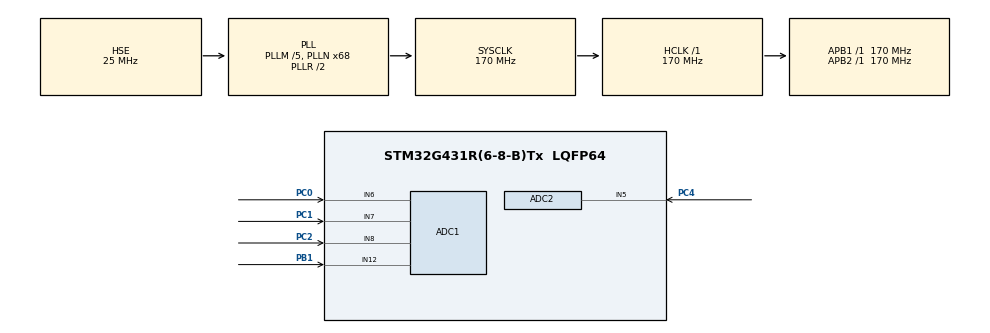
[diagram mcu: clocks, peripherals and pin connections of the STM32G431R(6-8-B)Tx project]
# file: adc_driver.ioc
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ADC1.Channel-1\#ChannelRegularConversion=ADC_CHANNEL_6
ADC1.Channel-2\#ChannelRegularConversion=ADC_CHANNEL_7
ADC1.Channel-3\#ChannelRegularConversion=ADC_CHANNEL_8
ADC1.Channel-4\#ChannelRegularConversion=ADC_CHANNEL_12
ADC1.ContinuousConvMode=ENABLE
ADC1.DMAContinuousRequests=ENABLE
ADC1.NbrOfConversion=4
ADC1.NbrOfConversionFlag=1
ADC1.OffsetNumber-1\#ChannelRegularConversion=ADC_OFFSET_NONE
ADC1.OffsetNumber-2\#ChannelRegularConversion=ADC_OFFSET_NONE
ADC1.OffsetNumber-3\#ChannelRegularConversion=ADC_OFFSET_NONE
ADC1.OffsetNumber-4\#ChannelRegularConversion=ADC_OFFSET_NONE
ADC1.Rank-1\#ChannelRegularConversion=1
ADC1.Rank-2\#ChannelRegularConversion=2
ADC1.Rank-3\#ChannelRegularConversion=3
ADC1.Rank-4\#ChannelRegularConversion=4
ADC1.SamplingTime-1\#ChannelRegularConversion=ADC_SAMPLETIME_47CYCLES_5
ADC1.SamplingTime-2\#ChannelRegularConversion=ADC_SAMPLETIME_47CYCLES_5
ADC1.SamplingTime-3\#ChannelRegularConversion=ADC_SAMPLETIME_47CYCLES_5
ADC1.SamplingTime-4\#ChannelRegularConversion=ADC_SAMPLETIME_47CYCLES_5
ADC1.master=1
ADC2.Channel-1\#ChannelRegularConversion=ADC_CHANNEL_5
ADC2.ContinuousConvMode=ENABLE
ADC2.DMAContinuousRequests=ENABLE
ADC2.NbrOfConversionFlag=1
ADC2.OffsetNumber-1\#ChannelRegularConversion=ADC_OFFSET_NONE
ADC2.Rank-1\#ChannelRegularConversion=1
ADC2.SamplingTime-1\#ChannelRegularConversion=ADC_SAMPLETIME_47CYCLES_5
Dma.ADC1.1.Direction=DMA_PERIPH_TO_MEMORY
Dma.ADC1.1.EventEnable=DISABLE
Dma.ADC1.1.Instance=DMA1_Channel2
Dma.ADC1.1.MemDataAlignment=DMA_MDATAALIGN_HALFWORD
Dma.ADC1.1.MemInc=DMA_MINC_ENABLE
Dma.ADC1.1.Mode=DMA_CIRCULAR
Dma.ADC1.1.PeriphDataAlignment=DMA_PDATAALIGN_HALFWORD
Dma.ADC1.1.PeriphInc=DMA_PINC_DISABLE
Dma.ADC1.1.Polarity=HAL_DMAMUX_REQ_GEN_RISING
Dma.ADC1.1.Priority=DMA_PRIORITY_LOW
Dma.ADC1.1.RequestNumber=1
Dma.ADC1.1.SignalID=NONE
Dma.ADC1.1.SyncEnable=DISABLE
Dma.ADC1.1.SyncPolarity=HAL_DMAMUX_SYNC_NO_EVENT
Dma.ADC1.1.SyncRequestNumber=1
Dma.ADC1.1.SyncSignalID=NONE
Dma.ADC2.0.Direction=DMA_PERIPH_TO_MEMORY
Dma.ADC2.0.EventEnable=DISABLE
Dma.ADC2.0.Instance=DMA1_Channel1
Dma.ADC2.0.MemDataAlignment=DMA_MDATAALIGN_HALFWORD
Dma.ADC2.0.MemInc=DMA_MINC_ENABLE
Dma.ADC2.0.Mode=DMA_CIRCULAR
Dma.ADC2.0.PeriphDataAlignment=DMA_PDATAALIGN_HALFWORD
Dma.ADC2.0.PeriphInc=DMA_PINC_DISABLE
Dma.ADC2.0.Polarity=HAL_DMAMUX_REQ_GEN_RISING
Dma.ADC2.0.Priority=DMA_PRIORITY_LOW
Dma.ADC2.0.RequestNumber=1
Dma.ADC2.0.SignalID=NONE
Dma.ADC2.0.SyncEnable=DISABLE
Dma.ADC2.0.SyncPolarity=HAL_DMAMUX_SYNC_NO_EVENT
Dma.ADC2.0.SyncRequestNumber=1
Dma.ADC2.0.SyncSignalID=NONE
Dma.Request0=ADC2
Dma.Request1=ADC1
Mcu.Family=STM32G4
Mcu.Name=STM32G431R(6-8-B)Tx
Mcu.Package=LQFP64
NVIC.DMA1_Channel1_IRQn=true\:0\:0\:false\:false\:true\:false\:true\:true
NVIC.DMA1_Channel2_IRQn=true\:0\:0\:false\:false\:true\:false\:true\:true
NVIC.PriorityGroup=NVIC_PRIORITYGROUP_4
PA13.Mode=Serial_Wire
PA13.Signal=SYS_JTMS-SWDIO
PA14.Mode=Serial_Wire
PA14.Signal=SYS_JTCK-SWCLK
PB1.Mode=IN12-Single-Ended
PB1.Signal=ADC1_IN12
PC0.Mode=IN6-Single-Ended
PC0.Signal=ADC1_IN6
PC1.Mode=IN7-Single-Ended
PC1.Signal=ADC1_IN7
PC2.Mode=IN8-Single-Ended
PC2.Signal=ADC1_IN8
PC4.Mode=IN5-Single-Ended
PC4.Signal=ADC2_IN5
PF0-OSC_IN.Mode=HSE-External-Oscillator
PF0-OSC_IN.Signal=RCC_OSC_IN
PF1-OSC_OUT.Mode=HSE-External-Oscillator
PF1-OSC_OUT.Signal=RCC_OSC_OUT
ProjectManager.HeapSize=0x200
ProjectManager.StackSize=0x400
ProjectManager.TargetToolchain=MDK-ARM V5.32
RCC.ADC12Freq_Value=170000000
RCC.AHBFreq_Value=170000000
RCC.APB1Freq_Value=170000000
RCC.APB1TimFreq_Value=170000000
RCC.APB2Freq_Value=170000000
RCC.APB2TimFreq_Value=170000000
RCC.CortexFreq_Value=170000000
RCC.EXTERNAL_CLOCK_VALUE=12288000
RCC.HCLKFreq_Value=170000000
RCC.HSE_VALUE=25000000
RCC.HSI48_VALUE=48000000
RCC.HSI_VALUE=16000000
RCC.LSE_VALUE=32768
RCC.PLLM=RCC_PLLM_DIV5
RCC.PLLN=68
RCC.PLLSourceVirtual=RCC_PLLSOURCE_HSE
RCC.SYSCLKFreq_VALUE=170000000
RCC.SYSCLKSource=RCC_SYSCLKSOURCE_PLLCLK
RCC.USBFreq_Value=170000000
RCC.VCOOutputFreq_Value=340000000
VP_SYS_VS_DBSignals.Mode=DisableDeadBatterySignals
board=custom

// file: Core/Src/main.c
/* USER CODE BEGIN Header */
/**
  ******************************************************************************
  * @file           : main.c
  * @brief          : Main program body
  ******************************************************************************
  * @attention
  *
  * Copyright (c) 2023 STMicroelectronics.
  * All rights reserved.
  *
  * This software is licensed under terms that can be found in the LICENSE file
  * in the root directory of this software component.
  * If no LICENSE file comes with this software, it is provided AS-IS.
  *
  ******************************************************************************
  */
/* USER CODE END Header */
#include "main.h"
#include "adc.h"
#include "dma.h"
#include "gpio.h"

/* USER CODE BEGIN Includes */
#include "adc_driver.h"
/* USER CODE END Includes */

void SystemClock_Config(void);

/* USER CODE BEGIN 0 */
uint16_t adc3_dma_value[5][5];
uint16_t result[4];
/* USER CODE END 0 */

int main(void)
{

  /* MCU Configuration--------------------------------------------------------*/

  /* Reset of all peripherals, Initializes the Flash interface and the Systick. */
  HAL_Init();

  /* Configure the system clock */
  SystemClock_Config();

  /* Initialize all configured peripherals */
  MX_GPIO_Init();
  MX_DMA_Init();
  MX_ADC1_Init();
  MX_ADC2_Init();
  /* USER CODE BEGIN 2 */
	adc_driver_init();
  /* USER CODE END 2 */

  /* Infinite loop */
  /* USER CODE BEGIN WHILE */
  while (1)
  {

		result[0] = adc1_median_filter(adc1_ch1);
		result[1] = adc1_median_filter(adc1_ch2);
		result[2] = adc1_median_filter(adc1_ch3);
		result[3] = adc1_median_filter(adc1_ch4);

    /* USER CODE END WHILE */

  }
}

void SystemClock_Config(void)
{
  RCC_OscInitTypeDef RCC_OscInitStruct = {0};
  RCC_ClkInitTypeDef RCC_ClkInitStruct = {0};

  /** Configure the main internal regulator output voltage
  */
  HAL_PWREx_ControlVoltageScaling(PWR_REGULATOR_VOLTAGE_SCALE1_BOOST);

  /** Initializes the RCC Oscillators according to the specified parameters
  * in the RCC_OscInitTypeDef structure.
  */
  RCC_OscInitStruct.OscillatorType = RCC_OSCILLATORTYPE_HSE;
  RCC_OscInitStruct.HSEState = RCC_HSE_ON;
  RCC_OscInitStruct.PLL.PLLState = RCC_PLL_ON;
  RCC_OscInitStruct.PLL.PLLSource = RCC_PLLSOURCE_HSE;
  RCC_OscInitStruct.PLL.PLLM = RCC_PLLM_DIV5;
  RCC_OscInitStruct.PLL.PLLN = 68;
  RCC_OscInitStruct.PLL.PLLP = RCC_PLLP_DIV2;
  RCC_OscInitStruct.PLL.PLLQ = RCC_PLLQ_DIV2;
  RCC_OscInitStruct.PLL.PLLR = RCC_PLLR_DIV2;
  if (HAL_RCC_OscConfig(&RCC_OscInitStruct) != HAL_OK)
  {
    Error_Handler();
  }

  /** Initializes the CPU, AHB and APB buses clocks
  */
  RCC_ClkInitStruct.ClockType = RCC_CLOCKTYPE_HCLK|RCC_CLOCKTYPE_SYSCLK
                              |RCC_CLOCKTYPE_PCLK1|RCC_CLOCKTYPE_PCLK2;
  RCC_ClkInitStruct.SYSCLKSource = RCC_SYSCLKSOURCE_PLLCLK;
  RCC_ClkInitStruct.AHBCLKDivider = RCC_SYSCLK_DIV1;
  RCC_ClkInitStruct.APB1CLKDivider = RCC_HCLK_DIV1;
  RCC_ClkInitStruct.APB2CLKDivider = RCC_HCLK_DIV1;

  if (HAL_RCC_ClockConfig(&RCC_ClkInitStruct, FLASH_LATENCY_4) != HAL_OK)
  {
    Error_Handler();
  }
}

void Error_Handler(void)
{
  __disable_irq();
  while (1)
  {
  }
}
